# CH32V205 register map
Vendor: WCH Ltd.; File version: 1.0
Registers are 32-bit, read-write, reset 0x0 unless marked. A register's access mark holds for its fields unless they carry their own. Offsets are from the block's base; [hi:lo] are bit positions; {n}, {i} and the like mark numbered series.

## USBPD — USBPD control register
Base 0x40027000
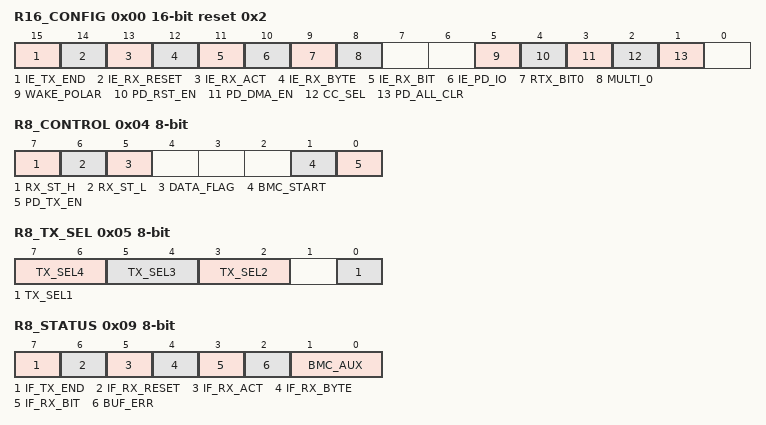
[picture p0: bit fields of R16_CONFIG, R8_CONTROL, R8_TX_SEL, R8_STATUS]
0x00 R16_CONFIG 16-bit reset 0x2 — PD configuration register
  [15] IE_TX_END — end of send interrupt enable
  [14] IE_RX_RESET — receive reset interrupt enable
  [13] IE_RX_ACT — receive finished interrupt enable
  [12] IE_RX_BYTE — receive byte interrupt enable
  [11] IE_RX_BIT — receive bit interrupt enable
  [10] IE_PD_IO — PD port interrupt enable
  [9] RTX_BIT0 — Send and receive the current value of shift register bit0
  [8] MULTI_0 — Receive a continuous multi-digit0 indication signal
  [5] WAKE_POLAR — wake-up level
  [4] PD_RST_EN — reset enable
  [3] PD_DMA_EN — PD_DMA enable
  [2] CC_SEL — communication port selection
  [1] PD_ALL_CLR — clear all interrupt enable
0x02 R16_BMC_CLK_CNT 16-bit — BMC sample clock counter
  [8:0] BMC_CLK_CNT — BMC sent/receive sample clock counter
0x04 R8_CONTROL 8-bit — sent/receive enable register
  [7] RX_ST_H — receive status high bit
  [6] RX_ST_L — receive status low bit
  [5] DATA_FLAG — data cache valid flag
  [1] BMC_START — BMC send a start signal
  [0] PD_TX_EN — sent/receive enable
0x05 R8_TX_SEL 8-bit — PD send sop selection register
  [7:6] TX_SEL4 — PD send type selection
  [5:4] TX_SEL3 — PD send type selection
  [3:2] TX_SEL2 — PD send type selection
  [0] TX_SEL1 — PD send type selection
0x06 R16_BMC_TX_SZ 16-bit — Total length sent
  [8:0] BMC_TX_SZ
0x08 R8_DATA_BUF 8-bit — DMA buffer data register
  [7:0] DATA_BUF — DMA DATA_BUFFER
0x09 R8_STATUS 8-bit access per field — PD interrupt flag register
  [7] IF_TX_END rw — Transmission completed interrupt flag
  [6] IF_RX_RESET rw — Receive reset interrupt flag
  [5] IF_RX_ACT rw — Receive completed interrupt flag
  [4] IF_RX_BYTE rw — Receive byte/SOP interrupt flag
  [3] IF_RX_BIT rw — Receive BIT/5BIT interrupt flag
  [2] BUF_ERR rw — BUFFER/DMA error interrupt flag
  [1:0] BMC_AUX ro — Indicating the current state
0x0A R16_BMC_BYTE_CNT 16-bit ro — byte count register
  [8:0] BMC_BYTE_CNT
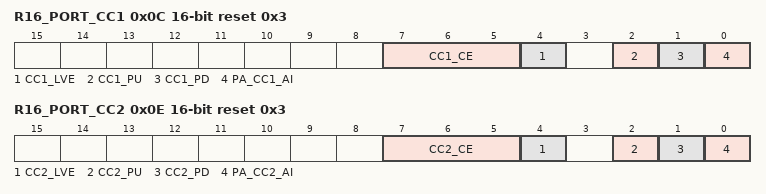
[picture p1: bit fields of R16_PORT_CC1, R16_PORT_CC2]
0x0C R16_PORT_CC1 16-bit reset 0x3 — port control register
  [7:5] CC1_CE — Enable port voltage comparator
  [4] CC1_LVE — port output lower voltage enable
  [2] CC1_PU — port pull-up current enable
  [1] CC1_PD — port pull-down resistor enable
  [0] PA_CC1_AI — port comparator simulates input
0x0E R16_PORT_CC2 16-bit reset 0x3 — port control register
  [7:5] CC2_CE — Enable port voltage comparator
  [4] CC2_LVE — port output lower voltage enable
  [2] CC2_PU — port pull-up current enable
  [1] CC2_PD — port pull-down resistor enable
  [0] PA_CC2_AI — port comparator simulates input
0x10 R16_DMA 16-bit — DMA cache start address register
  [15:0] USBPD_DMA_ADDR — USBPD_DMA cache address

## ESIG — ESIG configuration
Base 0x1FFFF7E0
0x00 FLACAP 16-bit ro — Flash capecity register
  [15:0] F_SIZE — F_SIZE/kByte
0x08 UNIID1 ro — UID register
  [31:0] U_ID — U_ID value
0x0C UNIID2 ro — UID register
  [31:0] U_ID — U_ID value
0x10 UNIID3 ro — Div register
  [31:0] AWU_APR — AWU_APR value

## PIOC — Programmable protocol I/O microcontroller
Base 0x40025C00
0x00 SFR_INDIR_PORT 8-bit access not given — Indirectly addressed data read/write ports
0x01 RSFR_INDIR_PORT2 8-bit access not given — Indirectly addresses the data read/write port of 2
0x02 SFR_PRG_COUNT 8-bit access not given — Program counters for the low bytes of the PC
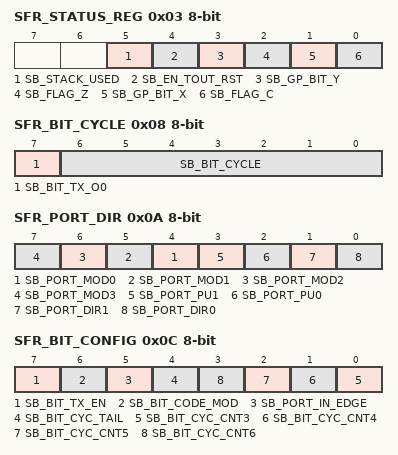
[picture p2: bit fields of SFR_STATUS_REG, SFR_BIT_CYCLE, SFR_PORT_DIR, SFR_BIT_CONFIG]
0x03 SFR_STATUS_REG 8-bit access not given — Status registers
  [5] SB_STACK_USED — Current stack usage flags
  [4] SB_EN_TOUT_RST — Timer Timeout Reset Enabled
  [3] SB_GP_BIT_Y — a generic bit variable Y, defined and used by the application
  [2] SB_FLAG_Z — ALU zero flag, whether the result is 00H
  [1] SB_GP_BIT_X — A generic bit variable X, defined and used by the application
  [0] SB_FLAG_C — ALU carry flag, whether the result is carried or produced by displacement
0x04 SFR_INDIR_ADDR 8-bit ro — Indirectly addressed address registers
0x05 SFR_TMR0_COUNT 8-bit ro — The counter register of timer 0
0x06 SFR_TIMER_CTRL 8-bit ro — The control register of the timer
0x07 SFR_TMR0_INIT 8-bit ro — The initial register of timer 0
0x08 SFR_BIT_CYCLE 8-bit — Periodic registers for coded bits
  [7] SB_BIT_TX_O0 — The raw bit data of the encoded bit to be sent, which is a double-buffered structure
  [6:0] SB_BIT_CYCLE — Sets the width of the encoded bits in clock cycles, which is the actual number of bits minus 1
0x09 SFR_INDIR_ADDR2 8-bit ro — Address registers for indirect address 2
0x0A SFR_PORT_DIR 8-bit ro — The port direction sets the register
  [n+4] SB_PORT_MOD{n} (n=0..3) — Pin mode control, host side defines the purpose
  [3] SB_PORT_PU1 — IO1 Pin Pull-Up Enables
  [2] SB_PORT_PU0 — IO0 Pin Pull-Up Enables
  [1] SB_PORT_DIR1 — IO1 Pin Direction Control
  [0] SB_PORT_DIR0 — IO0 Pin Direction Control
0x0B SFR_PORT_IO 8-bit ro — Port input and output registers
0x0C SFR_BIT_CONFIG 8-bit ro — Coded bit configuration registers
  [7] SB_BIT_TX_EN — The transmission of the coded bits is enabled
  [6] SB_BIT_CODE_MOD — How the coded bits are modulated
  [5] SB_PORT_IN_EDGE — Pin input level sampling point selection
  [4] SB_BIT_CYC_TAIL — Periodic state of the encoded bits
  [n-3] SB_BIT_CYC_CNT{n} (n=3..6) — The periodic timing state of the encoded bits
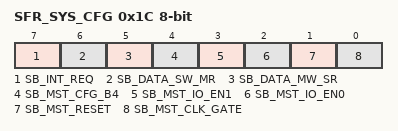
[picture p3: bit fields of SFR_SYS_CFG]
0x1C SFR_SYS_CFG 8-bit access per field — System configuration registers
  [7] SB_INT_REQ ro — Interrupt Request Activation Bits
  [6] SB_DATA_SW_MR ro — SFR_CTRL_RD wait to read the status bit
  [5] SB_DATA_MW_SR ro — SFR_CTRL_WR waiting to read the status bit
  [4] SB_MST_CFG_B4 wo — Configure information bits, software-defined uses
  [3] SB_MST_IO_EN1 wo — Mode and output control switches for IO1 pins
  [2] SB_MST_IO_EN0 wo — Mode and output control switches for IO0 pins
  [1] SB_MST_RESET wo — Force eMCU Reset
  [0] SB_MST_CLK_GATE wo — Global Clock Control for eMCUs
0x1D SFR_CTRL_RD 8-bit ro — The eMCU reads and writes and the host reads only the registers
0x1E SFR_CTRL_WR 8-bit — The host reads and writes and the eMCU reads only registers
0x1F SFR_DATA_EXCH 8-bit — Data exchange registers
{0x20+i} SFR_DATA_REG{i} 8-bit (i=0..31) — Data register {i}
